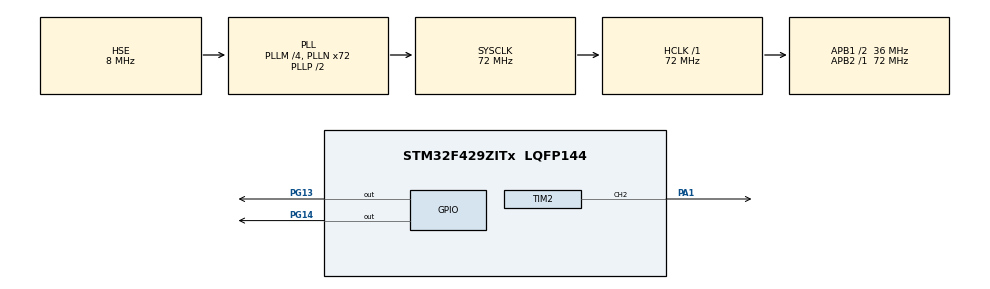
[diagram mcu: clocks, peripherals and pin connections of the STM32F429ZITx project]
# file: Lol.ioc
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Dma.Request0=TIM2_CH2/CH4
Dma.Request1=TIM4_CH3
Dma.Request2=TIM3_CH4/UP
Dma.Request3=TIM3_CH1/TRIG
Dma.TIM2_CH2/CH4.0.Direction=DMA_MEMORY_TO_PERIPH
Dma.TIM2_CH2/CH4.0.FIFOMode=DMA_FIFOMODE_DISABLE
Dma.TIM2_CH2/CH4.0.Instance=DMA1_Stream6
Dma.TIM2_CH2/CH4.0.MemDataAlignment=DMA_MDATAALIGN_WORD
Dma.TIM2_CH2/CH4.0.MemInc=DMA_MINC_ENABLE
Dma.TIM2_CH2/CH4.0.Mode=DMA_NORMAL
Dma.TIM2_CH2/CH4.0.PeriphDataAlignment=DMA_PDATAALIGN_WORD
Dma.TIM2_CH2/CH4.0.PeriphInc=DMA_PINC_DISABLE
Dma.TIM2_CH2/CH4.0.Priority=DMA_PRIORITY_LOW
Dma.TIM3_CH1/TRIG.3.Direction=DMA_PERIPH_TO_MEMORY
Dma.TIM3_CH1/TRIG.3.FIFOMode=DMA_FIFOMODE_DISABLE
Dma.TIM3_CH1/TRIG.3.Instance=DMA1_Stream4
Dma.TIM3_CH1/TRIG.3.MemDataAlignment=DMA_MDATAALIGN_HALFWORD
Dma.TIM3_CH1/TRIG.3.MemInc=DMA_MINC_ENABLE
Dma.TIM3_CH1/TRIG.3.Mode=DMA_NORMAL
Dma.TIM3_CH1/TRIG.3.PeriphDataAlignment=DMA_PDATAALIGN_HALFWORD
Dma.TIM3_CH1/TRIG.3.PeriphInc=DMA_PINC_DISABLE
Dma.TIM3_CH1/TRIG.3.Priority=DMA_PRIORITY_LOW
Dma.TIM3_CH4/UP.2.Direction=DMA_PERIPH_TO_MEMORY
Dma.TIM3_CH4/UP.2.FIFOMode=DMA_FIFOMODE_DISABLE
Dma.TIM3_CH4/UP.2.Instance=DMA1_Stream2
Dma.TIM3_CH4/UP.2.MemDataAlignment=DMA_MDATAALIGN_HALFWORD
Dma.TIM3_CH4/UP.2.MemInc=DMA_MINC_ENABLE
Dma.TIM3_CH4/UP.2.Mode=DMA_NORMAL
Dma.TIM3_CH4/UP.2.PeriphDataAlignment=DMA_PDATAALIGN_HALFWORD
Dma.TIM3_CH4/UP.2.PeriphInc=DMA_PINC_DISABLE
Dma.TIM3_CH4/UP.2.Priority=DMA_PRIORITY_LOW
Dma.TIM4_CH3.1.Direction=DMA_PERIPH_TO_MEMORY
Dma.TIM4_CH3.1.FIFOMode=DMA_FIFOMODE_DISABLE
Dma.TIM4_CH3.1.Instance=DMA1_Stream7
Dma.TIM4_CH3.1.MemDataAlignment=DMA_MDATAALIGN_HALFWORD
Dma.TIM4_CH3.1.MemInc=DMA_MINC_ENABLE
Dma.TIM4_CH3.1.Mode=DMA_NORMAL
Dma.TIM4_CH3.1.PeriphDataAlignment=DMA_PDATAALIGN_HALFWORD
Dma.TIM4_CH3.1.PeriphInc=DMA_PINC_DISABLE
Dma.TIM4_CH3.1.Priority=DMA_PRIORITY_LOW
Mcu.Family=STM32F4
Mcu.Name=STM32F429ZITx
Mcu.Package=LQFP144
NVIC.DMA1_Stream2_IRQn=true\:0\:0\:false\:false\:true\:false\:true
NVIC.DMA1_Stream4_IRQn=true\:0\:0\:false\:false\:true\:false\:true
NVIC.DMA1_Stream6_IRQn=true\:0\:0\:false\:false\:true\:false\:true
NVIC.DMA1_Stream7_IRQn=true\:0\:0\:false\:false\:true\:false\:true
NVIC.PriorityGroup=NVIC_PRIORITYGROUP_4
PA1.Signal=S_TIM2_CH2
PG13.Signal=GPIO_Output
PG14.Signal=GPIO_Output
PH0/OSC_IN.Mode=HSE-External-Oscillator
PH0/OSC_IN.Signal=RCC_OSC_IN
PH1/OSC_OUT.Mode=HSE-External-Oscillator
PH1/OSC_OUT.Signal=RCC_OSC_OUT
ProjectManager.HeapSize=0x200
ProjectManager.StackSize=0x400
ProjectManager.TargetToolchain=Makefile
RCC.48MHZClocksFreq_Value=36000000
RCC.AHBFreq_Value=72000000
RCC.APB1CLKDivider=RCC_HCLK_DIV2
RCC.APB1Freq_Value=36000000
RCC.APB1TimFreq_Value=72000000
RCC.APB2Freq_Value=72000000
RCC.APB2TimFreq_Value=72000000
RCC.CortexFreq_Value=72000000
RCC.HCLKFreq_Value=72000000
RCC.HSE_VALUE=8000000
RCC.HSI_VALUE=16000000
RCC.LSE_VALUE=32768
RCC.PLLM=4
RCC.PLLN=72
RCC.PLLSourceVirtual=RCC_PLLSOURCE_HSE
RCC.SYSCLKFreq_VALUE=72000000
RCC.SYSCLKSource=RCC_SYSCLKSOURCE_PLLCLK
RCC.VCOOutputFreq_Value=144000000
SH.S_TIM2_CH2.0=TIM2_CH2,PWM Generation2 CH2
TIM2.Channel-PWM\ Generation2\ CH2=TIM_CHANNEL_2
TIM2.Period=89
VP_TIM2_VS_ClockSourceINT.Mode=Internal
board=custom

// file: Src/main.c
/* USER CODE BEGIN Header */
/**
  ******************************************************************************
  * @file           : main.c
  * @brief          : Main program body
  ******************************************************************************
  * @attention
  *
  * <h2><center>&copy; Copyright (c) 2020 STMicroelectronics.
  * All rights reserved.</center></h2>
  *
  * This software component is licensed by ST under BSD 3-Clause license,
  * the "License"; You may not use this file except in compliance with the
  * License. You may obtain a copy of the License at:
  *                        opensource.org/licenses/BSD-3-Clause
  *
  ******************************************************************************
  */
/* USER CODE END Header */

#include "main.h"

/* USER CODE BEGIN Includes */
#include <string.h>

#include <stdlib.h>

#include <stdint.h>

#define DELAY_LEN 48
#define LED_COUNT 92
#define ARRAY_LEN DELAY_LEN + LED_COUNT*24

#define HIGH 65
#define LOW 26

uint16_t BUF_DMA [ARRAY_LEN] = {0};

#define BitIsSet(reg, bit) ((reg & (1<<bit)) != 0)
/* USER CODE END Includes */

TIM_HandleTypeDef htim2;
DMA_HandleTypeDef hdma_tim2_ch2_ch4;

void SystemClock_Config(void);
static void MX_GPIO_Init(void);
static void MX_DMA_Init(void);
static void MX_TIM2_Init(void);

/* USER CODE BEGIN 0 */

void ws2812_init(void)
{
  int i;
  for(i=DELAY_LEN;i<ARRAY_LEN;i++) BUF_DMA[i] = LOW;
}

void ws2812_sendRgb(uint8_t Rpixel , uint8_t Gpixel, uint8_t Bpixel, uint16_t posX)
{
  volatile uint16_t i;
  for(i=0;i<8;i++)
  {
    if (BitIsSet(Rpixel,(7-i)) == 1)
    {
      BUF_DMA[DELAY_LEN+posX*24+i+8] = HIGH;
    }else
    {
      BUF_DMA[DELAY_LEN+posX*24+i+8] = LOW;
    }
    if (BitIsSet(Gpixel,(7-i)) == 1)
    {
      BUF_DMA[DELAY_LEN+posX*24+i+0] = HIGH;
    }else
    {
      BUF_DMA[DELAY_LEN+posX*24+i+0] = LOW;
    }
    if (BitIsSet(Bpixel,(7-i)) == 1)
    {
      BUF_DMA[DELAY_LEN+posX*24+i+16] = HIGH;
    }else
    {
      BUF_DMA[DELAY_LEN+posX*24+i+16] = LOW;
    }
  }
}

/* USER CODE END 0 */

int main(void)
{

  /* MCU Configuration--------------------------------------------------------*/

  /* Reset of all peripherals, Initializes the Flash interface and the Systick. */
  HAL_Init();

  /* Configure the system clock */
  SystemClock_Config();

  /* Initialize all configured peripherals */
  MX_GPIO_Init();
  MX_DMA_Init();
  MX_TIM2_Init();

  /* Infinite loop */
  /* USER CODE BEGIN WHILE */

	ws2812_sendRgb(128, 0, 0, 0);
	ws2812_sendRgb(0, 128, 0, 1);
	ws2812_sendRgb(0, 0, 128, 2);
	ws2812_sendRgb(64, 64, 0, 3);
	HAL_TIM_PWM_Start_DMA(&htim2,TIM_CHANNEL_2,(uint32_t*)&BUF_DMA,ARRAY_LEN);

	HAL_GPIO_WritePin(GPIOG, GPIO_PIN_All, GPIO_PIN_SET);

  while (1)
  {
		HAL_GPIO_TogglePin(GPIOG, GPIO_PIN_13);
		HAL_Delay(1000);

    /* USER CODE END WHILE */

  }
}

void SystemClock_Config(void)
{
  RCC_OscInitTypeDef RCC_OscInitStruct = {0};
  RCC_ClkInitTypeDef RCC_ClkInitStruct = {0};

  /** Configure the main internal regulator output voltage
  */
  __HAL_RCC_PWR_CLK_ENABLE();
  __HAL_PWR_VOLTAGESCALING_CONFIG(PWR_REGULATOR_VOLTAGE_SCALE3);
  /** Initializes the CPU, AHB and APB busses clocks
  */
  RCC_OscInitStruct.OscillatorType = RCC_OSCILLATORTYPE_HSE;
  RCC_OscInitStruct.HSEState = RCC_HSE_ON;
  RCC_OscInitStruct.PLL.PLLState = RCC_PLL_ON;
  RCC_OscInitStruct.PLL.PLLSource = RCC_PLLSOURCE_HSE;
  RCC_OscInitStruct.PLL.PLLM = 4;
  RCC_OscInitStruct.PLL.PLLN = 72;
  RCC_OscInitStruct.PLL.PLLP = RCC_PLLP_DIV2;
  RCC_OscInitStruct.PLL.PLLQ = 4;
  if (HAL_RCC_OscConfig(&RCC_OscInitStruct) != HAL_OK)
  {
    Error_Handler();
  }
  /** Initializes the CPU, AHB and APB busses clocks
  */
  RCC_ClkInitStruct.ClockType = RCC_CLOCKTYPE_HCLK|RCC_CLOCKTYPE_SYSCLK
                              |RCC_CLOCKTYPE_PCLK1|RCC_CLOCKTYPE_PCLK2;
  RCC_ClkInitStruct.SYSCLKSource = RCC_SYSCLKSOURCE_PLLCLK;
  RCC_ClkInitStruct.AHBCLKDivider = RCC_SYSCLK_DIV1;
  RCC_ClkInitStruct.APB1CLKDivider = RCC_HCLK_DIV2;
  RCC_ClkInitStruct.APB2CLKDivider = RCC_HCLK_DIV1;

  if (HAL_RCC_ClockConfig(&RCC_ClkInitStruct, FLASH_LATENCY_2) != HAL_OK)
  {
    Error_Handler();
  }
}

static void MX_TIM2_Init(void)
{

  TIM_ClockConfigTypeDef sClockSourceConfig = {0};
  TIM_MasterConfigTypeDef sMasterConfig = {0};
  TIM_OC_InitTypeDef sConfigOC = {0};

  htim2.Instance = TIM2;
  htim2.Init.Prescaler = 0;
  htim2.Init.CounterMode = TIM_COUNTERMODE_UP;
  htim2.Init.Period = 89;
  htim2.Init.ClockDivision = TIM_CLOCKDIVISION_DIV1;
  htim2.Init.AutoReloadPreload = TIM_AUTORELOAD_PRELOAD_DISABLE;
  if (HAL_TIM_Base_Init(&htim2) != HAL_OK)
  {
    Error_Handler();
  }
  sClockSourceConfig.ClockSource = TIM_CLOCKSOURCE_INTERNAL;
  if (HAL_TIM_ConfigClockSource(&htim2, &sClockSourceConfig) != HAL_OK)
  {
    Error_Handler();
  }
  if (HAL_TIM_PWM_Init(&htim2) != HAL_OK)
  {
    Error_Handler();
  }
  sMasterConfig.MasterOutputTrigger = TIM_TRGO_RESET;
  sMasterConfig.MasterSlaveMode = TIM_MASTERSLAVEMODE_DISABLE;
  if (HAL_TIMEx_MasterConfigSynchronization(&htim2, &sMasterConfig) != HAL_OK)
  {
    Error_Handler();
  }
  sConfigOC.OCMode = TIM_OCMODE_PWM1;
  sConfigOC.Pulse = 0;
  sConfigOC.OCPolarity = TIM_OCPOLARITY_HIGH;
  sConfigOC.OCFastMode = TIM_OCFAST_DISABLE;
  if (HAL_TIM_PWM_ConfigChannel(&htim2, &sConfigOC, TIM_CHANNEL_2) != HAL_OK)
  {
    Error_Handler();
  }
  HAL_TIM_MspPostInit(&htim2);

}

static void MX_DMA_Init(void)
{

  /* DMA controller clock enable */
  __HAL_RCC_DMA1_CLK_ENABLE();

  /* DMA interrupt init */
  /* DMA1_Stream2_IRQn interrupt configuration */
  HAL_NVIC_SetPriority(DMA1_Stream2_IRQn, 0, 0);
  HAL_NVIC_EnableIRQ(DMA1_Stream2_IRQn);
  /* DMA1_Stream4_IRQn interrupt configuration */
  HAL_NVIC_SetPriority(DMA1_Stream4_IRQn, 0, 0);
  HAL_NVIC_EnableIRQ(DMA1_Stream4_IRQn);
  /* DMA1_Stream6_IRQn interrupt configuration */
  HAL_NVIC_SetPriority(DMA1_Stream6_IRQn, 0, 0);
  HAL_NVIC_EnableIRQ(DMA1_Stream6_IRQn);
  /* DMA1_Stream7_IRQn interrupt configuration */
  HAL_NVIC_SetPriority(DMA1_Stream7_IRQn, 0, 0);
  HAL_NVIC_EnableIRQ(DMA1_Stream7_IRQn);

}

static void MX_GPIO_Init(void)
{
  GPIO_InitTypeDef GPIO_InitStruct = {0};

  /* GPIO Ports Clock Enable */
  __HAL_RCC_GPIOH_CLK_ENABLE();
  __HAL_RCC_GPIOA_CLK_ENABLE();
  __HAL_RCC_GPIOG_CLK_ENABLE();

  /*Configure GPIO pin Output Level */
  HAL_GPIO_WritePin(GPIOG, GPIO_PIN_All, GPIO_PIN_RESET);

  /*Configure GPIO pins : PG13 PG14 */
  GPIO_InitStruct.Pin = GPIO_PIN_13|GPIO_PIN_14;
  GPIO_InitStruct.Mode = GPIO_MODE_OUTPUT_PP;
  GPIO_InitStruct.Pull = GPIO_NOPULL;
  GPIO_InitStruct.Speed = GPIO_SPEED_FREQ_LOW;
  HAL_GPIO_Init(GPIOG, &GPIO_InitStruct);

}

void Error_Handler(void)
{
}

/************************ (C) COPYRIGHT STMicroelectronics *****END OF FILE****/
